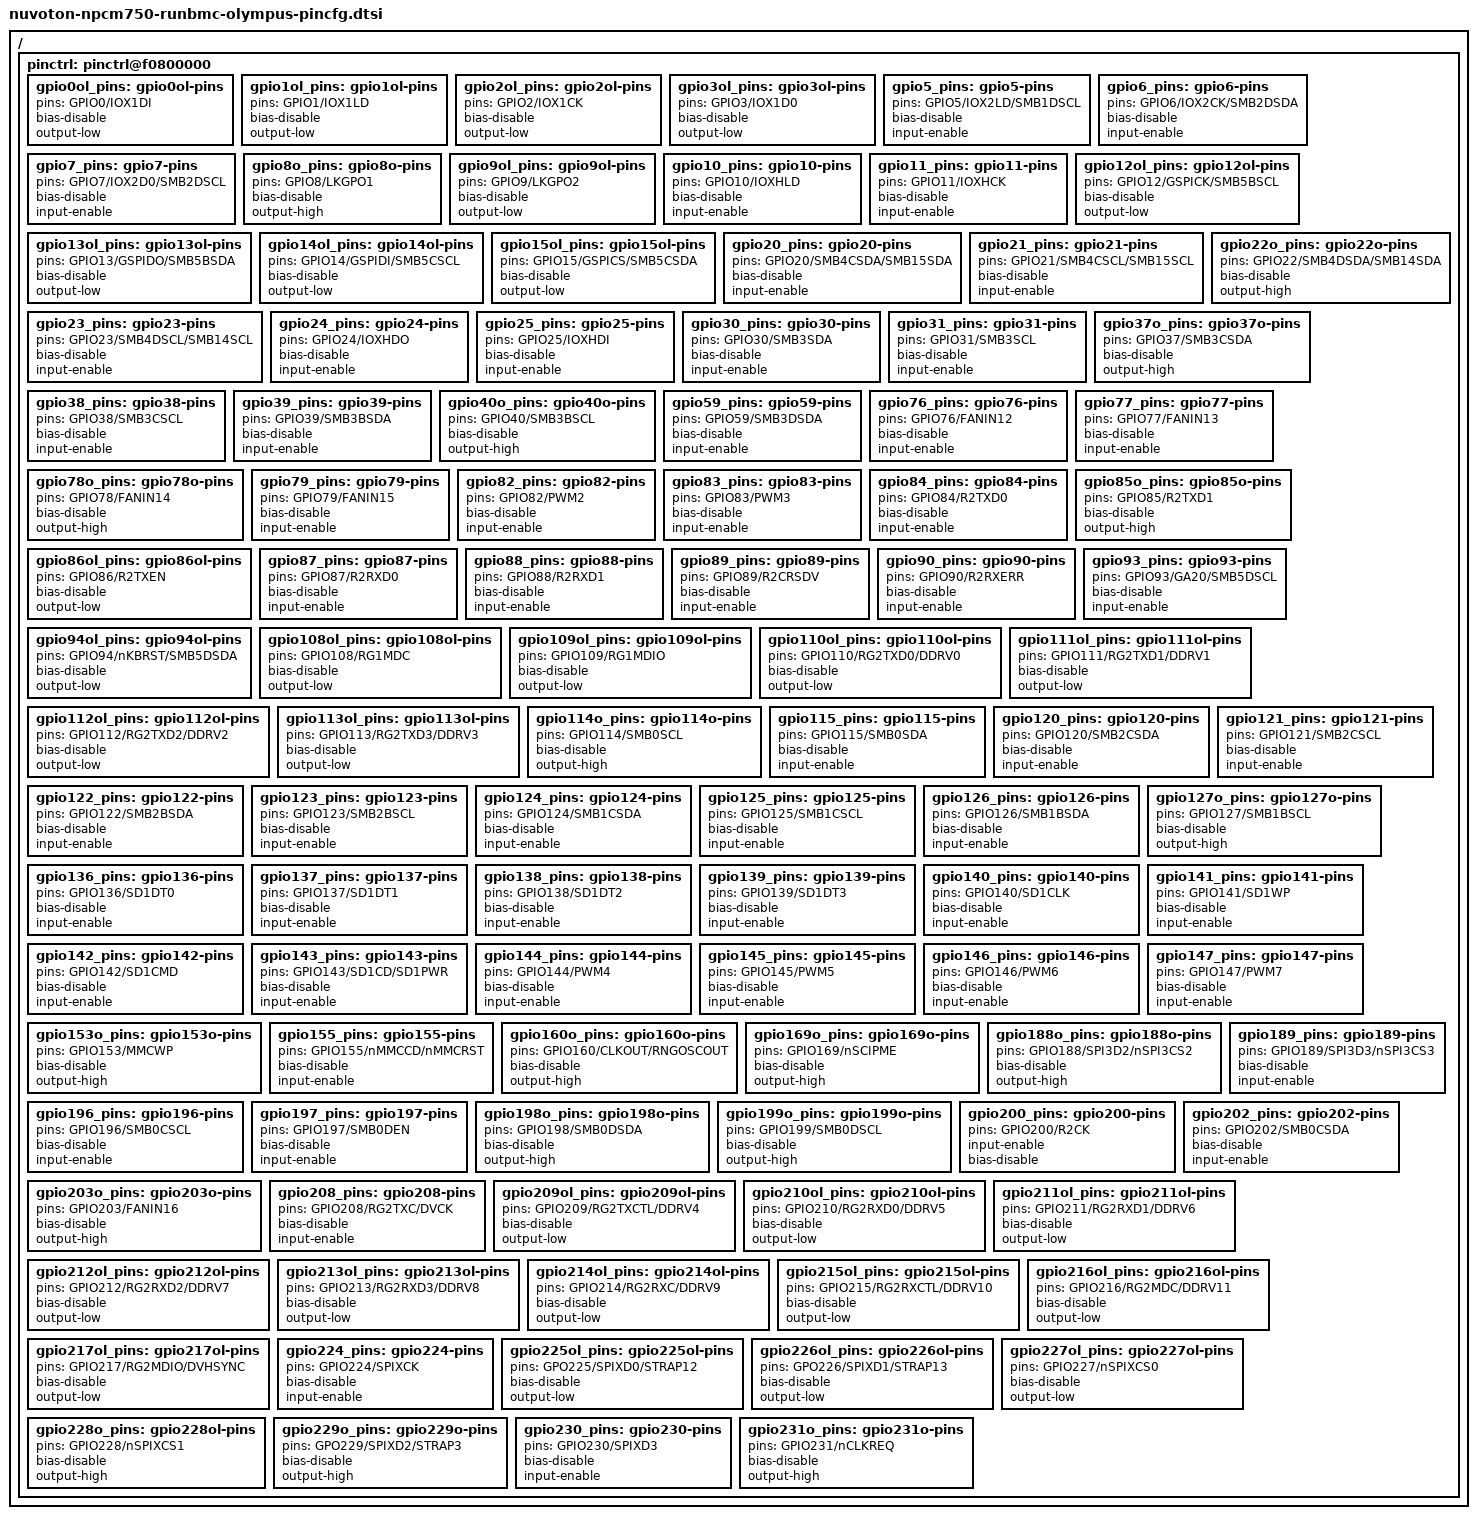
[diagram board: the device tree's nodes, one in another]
// SPDX-License-Identifier: GPL-2.0
// Copyright (c) 2019 Quanta Computer Inc. Samuel.Jiang@quantatw.com

/ {
	pinctrl: pinctrl@f0800000 {
		gpio0ol_pins: gpio0ol-pins {
			pins = "GPIO0/IOX1DI";
			bias-disable;
			output-low;
		};
		gpio1ol_pins: gpio1ol-pins {
			pins = "GPIO1/IOX1LD";
			bias-disable;
			output-low;
		};
		gpio2ol_pins: gpio2ol-pins {
			pins = "GPIO2/IOX1CK";
			bias-disable;
			output-low;
		};
		gpio3ol_pins: gpio3ol-pins {
			pins = "GPIO3/IOX1D0";
			bias-disable;
			output-low;
		};
		gpio5_pins: gpio5-pins {
			pins = "GPIO5/IOX2LD/SMB1DSCL";
			bias-disable;
			input-enable;
		};
		gpio6_pins: gpio6-pins {
			pins = "GPIO6/IOX2CK/SMB2DSDA";
			bias-disable;
			input-enable;
		};
		gpio7_pins: gpio7-pins {
			pins = "GPIO7/IOX2D0/SMB2DSCL";
			bias-disable;
			input-enable;
		};
		gpio8o_pins: gpio8o-pins {
			pins = "GPIO8/LKGPO1";
			bias-disable;
			output-high;
		};
		gpio9ol_pins: gpio9ol-pins {
			pins = "GPIO9/LKGPO2";
			bias-disable;
			output-low;
		};
		gpio10_pins: gpio10-pins {
			pins = "GPIO10/IOXHLD";
			bias-disable;
			input-enable;
		};
		gpio11_pins: gpio11-pins {
			pins = "GPIO11/IOXHCK";
			bias-disable;
			input-enable;
		};
		gpio12ol_pins: gpio12ol-pins {
			pins = "GPIO12/GSPICK/SMB5BSCL";
			bias-disable;
			output-low;
		};
		gpio13ol_pins: gpio13ol-pins {
			pins = "GPIO13/GSPIDO/SMB5BSDA";
			bias-disable;
			output-low;
		};
		gpio14ol_pins: gpio14ol-pins {
			pins = "GPIO14/GSPIDI/SMB5CSCL";
			bias-disable;
			output-low;
		};
		gpio15ol_pins: gpio15ol-pins {
			pins = "GPIO15/GSPICS/SMB5CSDA";
			bias-disable;
			output-low;
		};
		gpio20_pins: gpio20-pins {
			pins = "GPIO20/SMB4CSDA/SMB15SDA";
			bias-disable;
			input-enable;
		};
		gpio21_pins: gpio21-pins {
			pins = "GPIO21/SMB4CSCL/SMB15SCL";
			bias-disable;
			input-enable;
		};
		gpio22o_pins: gpio22o-pins {
			pins = "GPIO22/SMB4DSDA/SMB14SDA";
			bias-disable;
			output-high;
		};
		gpio23_pins: gpio23-pins {
			pins = "GPIO23/SMB4DSCL/SMB14SCL";
			bias-disable;
			input-enable;
		};
		gpio24_pins: gpio24-pins {
			pins = "GPIO24/IOXHDO";
			bias-disable;
			input-enable;
		};
		gpio25_pins: gpio25-pins {
			pins = "GPIO25/IOXHDI";
			bias-disable;
			input-enable;
		};
		gpio30_pins: gpio30-pins {
			pins = "GPIO30/SMB3SDA";
			bias-disable;
			input-enable;
		};
		gpio31_pins: gpio31-pins {
			pins = "GPIO31/SMB3SCL";
			bias-disable;
			input-enable;
		};
		gpio37o_pins: gpio37o-pins {
			pins = "GPIO37/SMB3CSDA";
			bias-disable;
			output-high;
		};
		gpio38_pins: gpio38-pins {
			pins = "GPIO38/SMB3CSCL";
			bias-disable;
			input-enable;
		};
		gpio39_pins: gpio39-pins {
			pins = "GPIO39/SMB3BSDA";
			bias-disable;
			input-enable;
		};
		gpio40o_pins: gpio40o-pins {
			pins = "GPIO40/SMB3BSCL";
			bias-disable;
			output-high;
		};
		gpio59_pins: gpio59-pins {
			pins = "GPIO59/SMB3DSDA";
			bias-disable;
			input-enable;
		};
		gpio76_pins: gpio76-pins {
			pins = "GPIO76/FANIN12";
			bias-disable;
			input-enable;
		};
		gpio77_pins: gpio77-pins {
			pins = "GPIO77/FANIN13";
			bias-disable;
			input-enable;
		};
		gpio78o_pins: gpio78o-pins {
			pins = "GPIO78/FANIN14";
			bias-disable;
			output-high;
		};
		gpio79_pins: gpio79-pins {
			pins = "GPIO79/FANIN15";
			bias-disable;
			input-enable;
		};
		gpio82_pins: gpio82-pins {
			pins = "GPIO82/PWM2";
			bias-disable;
			input-enable;
		};
		gpio83_pins: gpio83-pins {
			pins = "GPIO83/PWM3";
			bias-disable;
			input-enable;
		};
		gpio84_pins: gpio84-pins {
			pins = "GPIO84/R2TXD0";
			bias-disable;
			input-enable;
		};
		gpio85o_pins: gpio85o-pins {
			pins = "GPIO85/R2TXD1";
			bias-disable;
			output-high;
		};
		gpio86ol_pins: gpio86ol-pins {
			pins = "GPIO86/R2TXEN";
			bias-disable;
			output-low;
		};
		gpio87_pins: gpio87-pins {
			pins = "GPIO87/R2RXD0";
			bias-disable;
			input-enable;
		};
		gpio88_pins: gpio88-pins {
			pins = "GPIO88/R2RXD1";
			bias-disable;
			input-enable;
		};
		gpio89_pins: gpio89-pins {
			pins = "GPIO89/R2CRSDV";
			bias-disable;
			input-enable;
		};
		gpio90_pins: gpio90-pins {
			pins = "GPIO90/R2RXERR";
			bias-disable;
			input-enable;
		};
		gpio93_pins: gpio93-pins {
			pins = "GPIO93/GA20/SMB5DSCL";
			bias-disable;
			input-enable;
		};
		gpio94ol_pins: gpio94ol-pins {
			pins = "GPIO94/nKBRST/SMB5DSDA";
			bias-disable;
			output-low;
		};
		gpio108ol_pins: gpio108ol-pins {
			pins = "GPIO108/RG1MDC";
			bias-disable;
			output-low;
		};
		gpio109ol_pins: gpio109ol-pins {
			pins = "GPIO109/RG1MDIO";
			bias-disable;
			output-low;
		};
		gpio110ol_pins: gpio110ol-pins {
			pins = "GPIO110/RG2TXD0/DDRV0";
			bias-disable;
			output-low;
		};
		gpio111ol_pins: gpio111ol-pins {
			pins = "GPIO111/RG2TXD1/DDRV1";
			bias-disable;
			output-low;
		};
		gpio112ol_pins: gpio112ol-pins {
			pins = "GPIO112/RG2TXD2/DDRV2";
			bias-disable;
			output-low;
		};
		gpio113ol_pins: gpio113ol-pins {
			pins = "GPIO113/RG2TXD3/DDRV3";
			bias-disable;
			output-low;
		};
		gpio114o_pins: gpio114o-pins {
			pins = "GPIO114/SMB0SCL";
			bias-disable;
			output-high;
		};
		gpio115_pins: gpio115-pins {
			pins = "GPIO115/SMB0SDA";
			bias-disable;
			input-enable;
		};
		gpio120_pins: gpio120-pins {
			pins = "GPIO120/SMB2CSDA";
			bias-disable;
			input-enable;
		};
		gpio121_pins: gpio121-pins {
			pins = "GPIO121/SMB2CSCL";
			bias-disable;
			input-enable;
		};
		gpio122_pins: gpio122-pins {
			pins = "GPIO122/SMB2BSDA";
			bias-disable;
			input-enable;
		};
		gpio123_pins: gpio123-pins {
			pins = "GPIO123/SMB2BSCL";
			bias-disable;
			input-enable;
		};
		gpio124_pins: gpio124-pins {
			pins = "GPIO124/SMB1CSDA";
			bias-disable;
			input-enable;
		};
		gpio125_pins: gpio125-pins {
			pins = "GPIO125/SMB1CSCL";
			bias-disable;
			input-enable;
		};
		gpio126_pins: gpio126-pins {
			pins = "GPIO126/SMB1BSDA";
			bias-disable;
			input-enable;
		};
		gpio127o_pins: gpio127o-pins {
			pins = "GPIO127/SMB1BSCL";
			bias-disable;
			output-high;
		};
		gpio136_pins: gpio136-pins {
			pins = "GPIO136/SD1DT0";
			bias-disable;
			input-enable;
		};
		gpio137_pins: gpio137-pins {
			pins = "GPIO137/SD1DT1";
			bias-disable;
			input-enable;
		};
		gpio138_pins: gpio138-pins {
			pins = "GPIO138/SD1DT2";
			bias-disable;
			input-enable;
		};
		gpio139_pins: gpio139-pins {
			pins = "GPIO139/SD1DT3";
			bias-disable;
			input-enable;
		};
		gpio140_pins: gpio140-pins {
			pins = "GPIO140/SD1CLK";
			bias-disable;
			input-enable;
		};
		gpio141_pins: gpio141-pins {
			pins = "GPIO141/SD1WP";
			bias-disable;
			input-enable;
		};
		gpio142_pins: gpio142-pins {
			pins = "GPIO142/SD1CMD";
			bias-disable;
			input-enable;
		};
		gpio143_pins: gpio143-pins {
			pins = "GPIO143/SD1CD/SD1PWR";
			bias-disable;
			input-enable;
		};
		gpio144_pins: gpio144-pins {
			pins = "GPIO144/PWM4";
			bias-disable;
			input-enable;
		};
		gpio145_pins: gpio145-pins {
			pins = "GPIO145/PWM5";
			bias-disable;
			input-enable;
		};
		gpio146_pins: gpio146-pins {
			pins = "GPIO146/PWM6";
			bias-disable;
			input-enable;
		};
		gpio147_pins: gpio147-pins {
			pins = "GPIO147/PWM7";
			bias-disable;
			input-enable;
		};
		gpio153o_pins: gpio153o-pins {
			pins = "GPIO153/MMCWP";
			bias-disable;
			output-high;
		};
		gpio155_pins: gpio155-pins {
			pins = "GPIO155/nMMCCD/nMMCRST";
			bias-disable;
			input-enable;
		};
		gpio160o_pins: gpio160o-pins {
			pins = "GPIO160/CLKOUT/RNGOSCOUT";
			bias-disable;
			output-high;
		};
		gpio169o_pins: gpio169o-pins {
			pins = "GPIO169/nSCIPME";
			bias-disable;
			output-high;
		};
		gpio188o_pins: gpio188o-pins {
			pins = "GPIO188/SPI3D2/nSPI3CS2";
			bias-disable;
			output-high;
		};
		gpio189_pins: gpio189-pins {
			pins = "GPIO189/SPI3D3/nSPI3CS3";
			bias-disable;
			input-enable;
		};
		gpio196_pins: gpio196-pins {
			pins = "GPIO196/SMB0CSCL";
			bias-disable;
			input-enable;
		};
		gpio197_pins: gpio197-pins {
			pins = "GPIO197/SMB0DEN";
			bias-disable;
			input-enable;
		};
		gpio198o_pins: gpio198o-pins {
			pins = "GPIO198/SMB0DSDA";
			bias-disable;
			output-high;
		};
		gpio199o_pins: gpio199o-pins {
			pins = "GPIO199/SMB0DSCL";
			bias-disable;
			output-high;
		};
		gpio200_pins: gpio200-pins {
			pins = "GPIO200/R2CK";
			input-enable;
			bias-disable;
		};
		gpio202_pins: gpio202-pins {
			pins = "GPIO202/SMB0CSDA";
			bias-disable;
			input-enable;
		};
		gpio203o_pins: gpio203o-pins {
			pins = "GPIO203/FANIN16";
			bias-disable;
			output-high;
		};
		gpio208_pins: gpio208-pins {
			pins = "GPIO208/RG2TXC/DVCK";
			bias-disable;
			input-enable;
		};
		gpio209ol_pins: gpio209ol-pins {
			pins = "GPIO209/RG2TXCTL/DDRV4";
			bias-disable;
			output-low;
		};
		gpio210ol_pins: gpio210ol-pins {
			pins = "GPIO210/RG2RXD0/DDRV5";
			bias-disable;
			output-low;
		};
		gpio211ol_pins: gpio211ol-pins {
			pins = "GPIO211/RG2RXD1/DDRV6";
			bias-disable;
			output-low;
		};
		gpio212ol_pins: gpio212ol-pins {
			pins = "GPIO212/RG2RXD2/DDRV7";
			bias-disable;
			output-low;
		};
		gpio213ol_pins: gpio213ol-pins {
			pins = "GPIO213/RG2RXD3/DDRV8";
			bias-disable;
			output-low;
		};
		gpio214ol_pins: gpio214ol-pins {
			pins = "GPIO214/RG2RXC/DDRV9";
			bias-disable;
			output-low;
		};
		gpio215ol_pins: gpio215ol-pins {
			pins = "GPIO215/RG2RXCTL/DDRV10";
			bias-disable;
			output-low;
		};
		gpio216ol_pins: gpio216ol-pins {
			pins = "GPIO216/RG2MDC/DDRV11";
			bias-disable;
			output-low;
		};
		gpio217ol_pins: gpio217ol-pins {
			pins = "GPIO217/RG2MDIO/DVHSYNC";
			bias-disable;
			output-low;
		};
		gpio224_pins: gpio224-pins {
			pins = "GPIO224/SPIXCK";
			bias-disable;
			input-enable;
		};
		gpio225ol_pins: gpio225ol-pins {
			pins = "GPO225/SPIXD0/STRAP12";
			bias-disable;
			output-low;
		};
		gpio226ol_pins: gpio226ol-pins {
			pins = "GPO226/SPIXD1/STRAP13";
			bias-disable;
			output-low;
		};
		gpio227ol_pins: gpio227ol-pins {
			pins = "GPIO227/nSPIXCS0";
			bias-disable;
			output-low;
		};
		gpio228o_pins: gpio228ol-pins {
			pins = "GPIO228/nSPIXCS1";
			bias-disable;
			output-high;
		};
		gpio229o_pins: gpio229o-pins {
			pins = "GPO229/SPIXD2/STRAP3";
			bias-disable;
			output-high;
		};
		gpio230_pins: gpio230-pins {
			pins = "GPIO230/SPIXD3";
			bias-disable;
			input-enable;
		};
		gpio231o_pins: gpio231o-pins {
			pins = "GPIO231/nCLKREQ";
			bias-disable;
			output-high;
		};
	};
};
